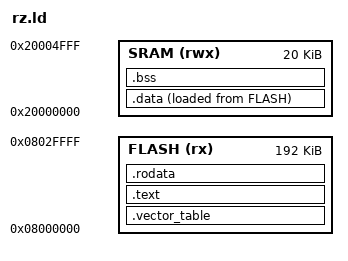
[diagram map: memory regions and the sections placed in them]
MEMORY
{
    FLASH(rx)   : ORIGIN = 0x08000000, LENGTH = 192K
    SRAM(rwx)   : ORIGIN = 0x20000000, LENGTH = 20K
}

SECTIONS
{
    .vector_table :
    {
        . = ALIGN(4);
        *(.vector_table)
        . = ALIGN(4);
    } > FLASH

    .text :
    {
        . = ALIGN(4);
        *(.text)
        *(.text*)
        *(.glue_7)
        *(.glue_7t)
        *(.eh_frame)
        . = ALIGN(4);
        _etext = .;
    } > FLASH

    .rodata :
    {
        . = ALIGN(4);
        *(.rodata)
        *(.rodata*)
        . = ALIGN(4);
    } > FLASH

    _sidata = LOADADDR(.data);

    .data :
    {
        _sdata = .;
        *(.data)
        *(.data*)
        . = ALIGN(4);
        _edata = .;
    } > SRAM AT> FLASH

    .bss :
    {
        _sbss = .;
        *(.bss)
        *(.bss*)
        . = ALIGN(4);
        _ebss = .;
    } > SRAM
}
